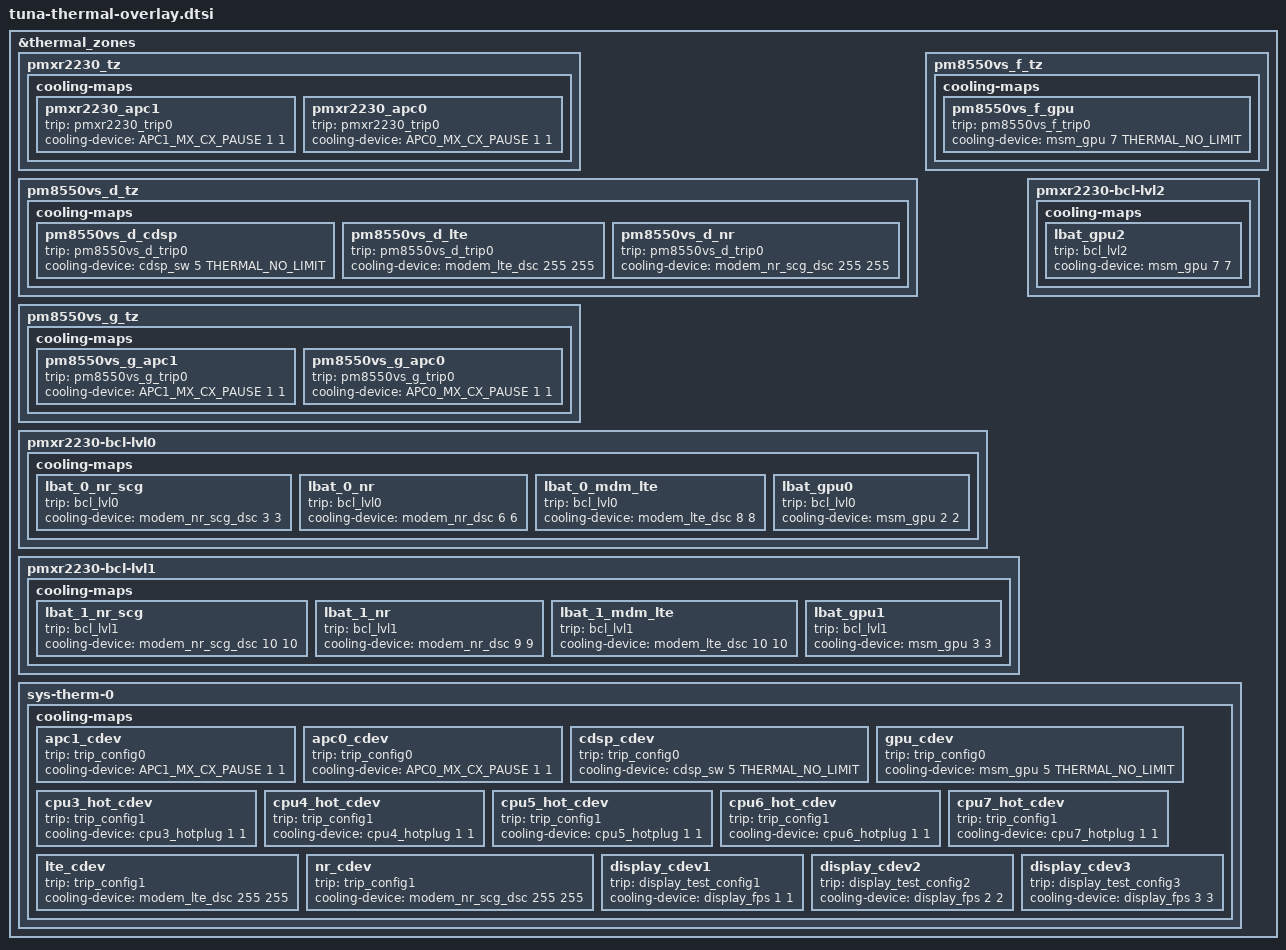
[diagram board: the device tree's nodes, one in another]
// SPDX-License-Identifier: BSD-3-Clause
/*
 * Copyright (c) 2024 Qualcomm Innovation Center, Inc. All rights reserved.
 */

#include <dt-bindings/thermal/thermal_qti.h>

&thermal_zones {
	pmxr2230_tz {
		cooling-maps {
			pmxr2230_apc1 {
				trip = <&pmxr2230_trip0>;
				cooling-device = <&APC1_MX_CX_PAUSE 1 1>;
			};

			pmxr2230_apc0 {
				trip = <&pmxr2230_trip0>;
				cooling-device = <&APC0_MX_CX_PAUSE 1 1>;
			};
		};
	};

	pm8550vs_d_tz {
		cooling-maps {
			pm8550vs_d_cdsp {
				trip = <&pm8550vs_d_trip0>;
				cooling-device = <&cdsp_sw 5 THERMAL_NO_LIMIT>;
			};

			pm8550vs_d_lte {
				trip = <&pm8550vs_d_trip0>;
				cooling-device = <&modem_lte_dsc 255 255>;
			};

			pm8550vs_d_nr {
				trip = <&pm8550vs_d_trip0>;
				cooling-device = <&modem_nr_scg_dsc 255 255>;
			};
		};
	};

	pm8550vs_f_tz {
		cooling-maps {
			pm8550vs_f_gpu {
				trip = <&pm8550vs_f_trip0>;
				cooling-device = <&msm_gpu 7 THERMAL_NO_LIMIT>;
			};
		};
	};

	pm8550vs_g_tz {
		cooling-maps {
			pm8550vs_g_apc1 {
				trip = <&pm8550vs_g_trip0>;
				cooling-device = <&APC1_MX_CX_PAUSE 1 1>;
			};

			pm8550vs_g_apc0 {
				trip = <&pm8550vs_g_trip0>;
				cooling-device = <&APC0_MX_CX_PAUSE 1 1>;
			};
		};
	};

	pmxr2230-bcl-lvl0 {
		cooling-maps {
			lbat_0_nr_scg {
				trip = <&bcl_lvl0>;
				cooling-device = <&modem_nr_scg_dsc 3 3>;
			};

			lbat_0_nr {
				trip = <&bcl_lvl0>;
				cooling-device = <&modem_nr_dsc 6 6>;
			};

			lbat_0_mdm_lte {
				trip = <&bcl_lvl0>;
				cooling-device = <&modem_lte_dsc 8 8>;
			};

			lbat_gpu0 {
				trip = <&bcl_lvl0>;
				cooling-device = <&msm_gpu 2 2>;
			};
		};
	};

	pmxr2230-bcl-lvl1 {
		cooling-maps {
			lbat_1_nr_scg {
				trip = <&bcl_lvl1>;
				cooling-device = <&modem_nr_scg_dsc 10 10>;
			};

			lbat_1_nr {
				trip = <&bcl_lvl1>;
				cooling-device = <&modem_nr_dsc 9 9>;
			};

			lbat_1_mdm_lte {
				trip = <&bcl_lvl1>;
				cooling-device = <&modem_lte_dsc 10 10>;
			};

			lbat_gpu1 {
				trip = <&bcl_lvl1>;
				cooling-device = <&msm_gpu 3 3>;
			};
		};
	};

	pmxr2230-bcl-lvl2 {
		cooling-maps {
			lbat_gpu2 {
				trip = <&bcl_lvl2>;
				cooling-device = <&msm_gpu 7 7>;
			};
		};
	};

	sys-therm-0 {
		cooling-maps {
			apc1_cdev {
				trip = <&trip_config0>;
				cooling-device = <&APC1_MX_CX_PAUSE 1 1>;
			};

			apc0_cdev {
				trip = <&trip_config0>;
				cooling-device = <&APC0_MX_CX_PAUSE 1 1>;
			};

			cdsp_cdev {
				trip = <&trip_config0>;
				cooling-device = <&cdsp_sw 5 THERMAL_NO_LIMIT>;
			};

			gpu_cdev {
				trip = <&trip_config0>;
				cooling-device = <&msm_gpu 5 THERMAL_NO_LIMIT>;
			};

			cpu3_hot_cdev {
				trip = <&trip_config1>;
				cooling-device = <&cpu3_hotplug 1 1>;
			};

			cpu4_hot_cdev {
				trip = <&trip_config1>;
				cooling-device = <&cpu4_hotplug 1 1>;
			};

			cpu5_hot_cdev {
				trip = <&trip_config1>;
				cooling-device = <&cpu5_hotplug 1 1>;
			};

			cpu6_hot_cdev {
				trip = <&trip_config1>;
				cooling-device = <&cpu6_hotplug 1 1>;
			};

			cpu7_hot_cdev {
				trip = <&trip_config1>;
				cooling-device = <&cpu7_hotplug 1 1>;
			};

			lte_cdev {
				trip = <&trip_config1>;
				cooling-device = <&modem_lte_dsc 255 255>;
			};

			nr_cdev {
				trip = <&trip_config1>;
				cooling-device = <&modem_nr_scg_dsc 255 255>;
			};

			display_cdev1 {
				trip = <&display_test_config1>;
				cooling-device = <&display_fps 1 1>;
			};

			display_cdev2 {
				trip = <&display_test_config2>;
				cooling-device = <&display_fps 2 2>;
			};

			display_cdev3 {
				trip = <&display_test_config3>;
				cooling-device = <&display_fps 3 3>;
			};
		};
	};
};
